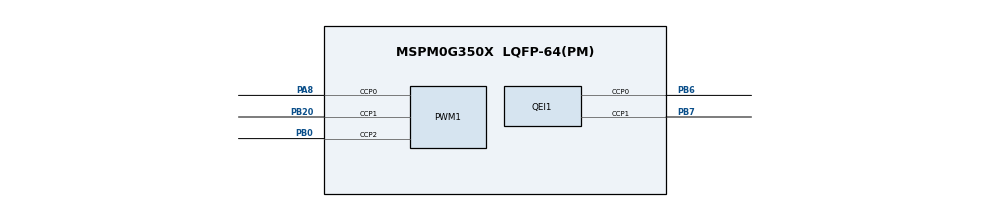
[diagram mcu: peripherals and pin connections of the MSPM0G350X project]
/**
 * @cliArgs --device "MSPM0G350X" --part "Default" --package "LQFP-64(PM)" --product "mspm0_sdk@2.06.00.05"
 * @versions {"tool":"1.21.0+3721"}
 */

/**
 * Import the modules used in this configuration.
 */
const GPIO   = scripting.addModule("/ti/driverlib/GPIO", {}, false);
const GPIO1  = GPIO.addInstance();
const GPIO2  = GPIO.addInstance();
const GPIO3  = GPIO.addInstance();
const PWM    = scripting.addModule("/ti/driverlib/PWM", {}, false);
const PWM1   = PWM.addInstance();
const QEI    = scripting.addModule("/ti/driverlib/QEI", {}, false);
const QEI1   = QEI.addInstance();
const SYSCTL = scripting.addModule("/ti/driverlib/SYSCTL");
const TIMER  = scripting.addModule("/ti/driverlib/TIMER", {}, false);
const TIMER1 = TIMER.addInstance();

/**
 * Write custom configuration values to the imported modules.
 */
GPIO1.port                           = "PORTA";
GPIO1.$name                          = "GPIO_OLED_13";
GPIO1.associatedPins.create(2);
GPIO1.associatedPins[0].$name        = "GPIO_SCK";
GPIO1.associatedPins[0].initialValue = "SET";
GPIO1.associatedPins[0].assignedPin  = "31";
GPIO1.associatedPins[1].$name        = "GPIO_SDA";
GPIO1.associatedPins[1].assignedPin  = "28";
GPIO1.associatedPins[1].initialValue = "SET";

const Board = scripting.addModule("/ti/driverlib/Board", {}, false);

GPIO2.port                           = "PORTA";
GPIO2.$name                          = "GPIO_LEDS";
GPIO2.associatedPins[0].$name        = "LED_1";
GPIO2.associatedPins[0].assignedPin  = "0";
GPIO2.associatedPins[0].initialValue = "SET";

GPIO3.$name                              = "GPIO_EC11";
GPIO3.associatedPins[0].direction        = "INPUT";
GPIO3.associatedPins[0].assignedPin      = "18";
GPIO3.associatedPins[0].assignedPort     = "PORTA";
GPIO3.associatedPins[0].$name            = "SW";
GPIO3.associatedPins[0].interruptEn      = true;
GPIO3.associatedPins[0].internalResistor = "PULL_UP";
GPIO3.associatedPins[0].polarity         = "RISE_FALL";

PWM1.ccIndex                            = [0,1,2];
PWM1.$name                              = "LED_rgb";
PWM1.timerStartTimer                    = true;
PWM1.clockDivider                       = 2;
PWM1.peripheral.$assign                 = "TIMA0";
PWM1.peripheral.ccp0Pin.$assign         = "PA8";
PWM1.peripheral.ccp1Pin.$assign         = "PB20";
PWM1.peripheral.ccp2Pin.$assign         = "PB0";
PWM1.PWM_CHANNEL_0.$name                = "ti_driverlib_pwm_PWMTimerCC0";
PWM1.PWM_CHANNEL_0.dutyCycle            = 50;
PWM1.PWM_CHANNEL_0.invert               = true;
PWM1.PWM_CHANNEL_1.$name                = "ti_driverlib_pwm_PWMTimerCC1";
PWM1.PWM_CHANNEL_1.ccValue              = 1000;
PWM1.PWM_CHANNEL_1.invert               = true;
PWM1.ccp0PinConfig.direction            = scripting.forceWrite("OUTPUT");
PWM1.ccp0PinConfig.hideOutputInversion  = scripting.forceWrite(false);
PWM1.ccp0PinConfig.onlyInternalResistor = scripting.forceWrite(false);
PWM1.ccp0PinConfig.passedPeripheralType = scripting.forceWrite("Digital");
PWM1.ccp0PinConfig.$name                = "ti_driverlib_gpio_GPIOPinGeneric1";
PWM1.ccp1PinConfig.direction            = scripting.forceWrite("OUTPUT");
PWM1.ccp1PinConfig.hideOutputInversion  = scripting.forceWrite(false);
PWM1.ccp1PinConfig.onlyInternalResistor = scripting.forceWrite(false);
PWM1.ccp1PinConfig.passedPeripheralType = scripting.forceWrite("Digital");
PWM1.ccp1PinConfig.$name                = "ti_driverlib_gpio_GPIOPinGeneric2";
PWM1.PWM_CHANNEL_2.$name                = "ti_driverlib_pwm_PWMTimerCC2";
PWM1.PWM_CHANNEL_2.ccValue              = 1000;
PWM1.PWM_CHANNEL_2.invert               = true;
PWM1.ccp2PinConfig.direction            = scripting.forceWrite("OUTPUT");
PWM1.ccp2PinConfig.hideOutputInversion  = scripting.forceWrite(false);
PWM1.ccp2PinConfig.onlyInternalResistor = scripting.forceWrite(false);
PWM1.ccp2PinConfig.passedPeripheralType = scripting.forceWrite("Digital");
PWM1.ccp2PinConfig.$name                = "ti_driverlib_gpio_GPIOPinGeneric3";

QEI1.$name                              = "TIMER_QEI";
QEI1.peripheral.$assign                 = "TIMG8";
QEI1.peripheral.ccp0Pin.$assign         = "PB6";
QEI1.peripheral.ccp1Pin.$assign         = "PB7";
QEI1.ccp0PinConfig.$name                = "ti_driverlib_gpio_GPIOPinGeneric0";
QEI1.ccp0PinConfig.hideOutputInversion  = scripting.forceWrite(false);
QEI1.ccp0PinConfig.onlyInternalResistor = scripting.forceWrite(false);
QEI1.ccp0PinConfig.passedPeripheralType = scripting.forceWrite("Digital");
QEI1.ccp1PinConfig.$name                = "ti_driverlib_gpio_GPIOPinGeneric4";
QEI1.ccp1PinConfig.hideOutputInversion  = scripting.forceWrite(false);
QEI1.ccp1PinConfig.onlyInternalResistor = scripting.forceWrite(false);
QEI1.ccp1PinConfig.passedPeripheralType = scripting.forceWrite("Digital");

SYSCTL.forceDefaultClkConfig = true;
SYSCTL.clockTreeEn           = true;

TIMER1.timerPeriod        = "1 ms";
TIMER1.interrupts         = ["ZERO"];
TIMER1.$name              = "TIMER_MS";
TIMER1.timerClkPrescale   = 32;
TIMER1.timerMode          = "PERIODIC_UP";
TIMER1.peripheral.$assign = "TIMG6";

/**
 * Pinmux solution for unlocked pins/peripherals. This ensures that minor changes to the automatic solver in a future
 * version of the tool will not impact the pinmux you originally saw.  These lines can be completely deleted in order to
 * re-solve from scratch.
 */
GPIO1.associatedPins[0].pin.$suggestSolution = "PA31";
GPIO1.associatedPins[1].pin.$suggestSolution = "PA28";
Board.peripheral.$suggestSolution            = "DEBUGSS";
Board.peripheral.swclkPin.$suggestSolution   = "PA20";
Board.peripheral.swdioPin.$suggestSolution   = "PA19";
GPIO2.associatedPins[0].pin.$suggestSolution = "PA0";
GPIO3.associatedPins[0].pin.$suggestSolution = "PA18";
